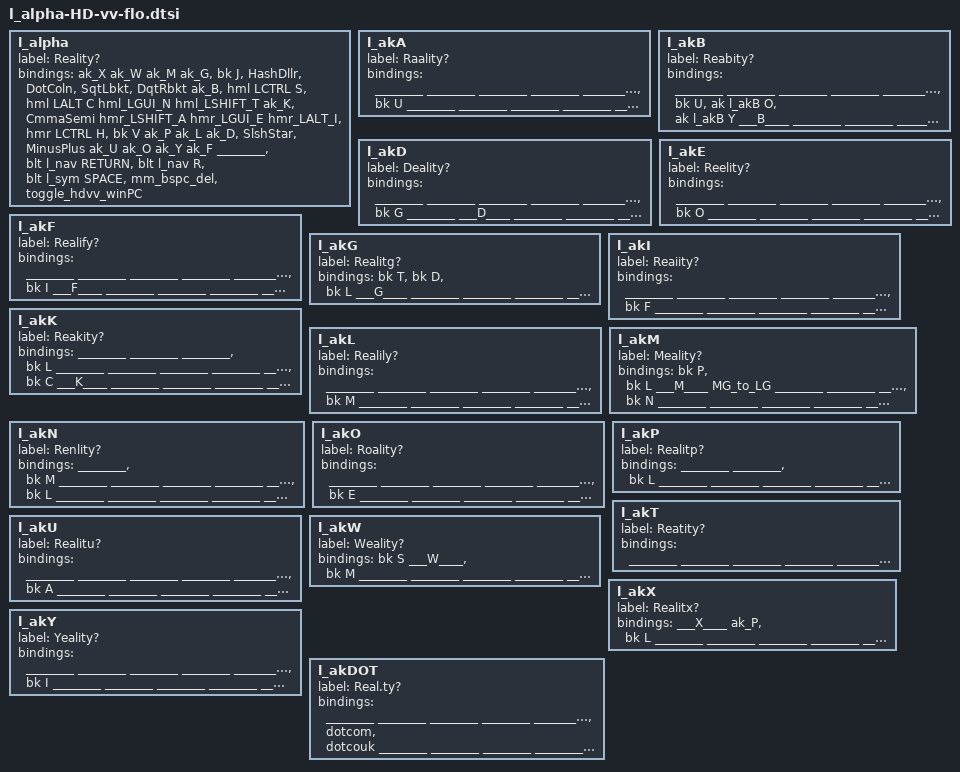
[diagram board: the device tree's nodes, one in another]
#define ________  &trans
#define ___A____ ________
#define ___B____ ________
#define ___C____ ________
#define ___D____ ________
#define ___E____ ________
#define ___F____ ________
#define ___G____ ________
#define ___H____ ________
#define ___I____ ________
#define ___J____ ________
#define ___K____ ________
#define ___L____ ________
#define ___M____ ________
#define ___N____ ________
#define ___O____ ________
#define ___P____ ________
#define ___Q____ ________
#define ___R____ ________
#define ___S____ ________
#define ___T____ ________
#define ___U____ ________
#define ___V____ ________
#define ___W____ ________
#define ___X____ ________
#define ___Y____ ________
#define ___Z____ ________
#define _DOT____ ________


#define GK_to_LK &replace_char_with_bigram L K
#define MG_to_LG &replace_char_with_bigram L G
#define TK_to_CK &replace_char_with_bigram C K


#define XXX 0
// Second param is ignored, so using XXX
#define hml_LGUI_N   &hml_N LGUI   XXX
#define hml_LSHIFT_T &hml_T LSHIFT XXX
#define hmr_LSHIFT_A &hmr_A LSHIFT XXX
#define hmr_LGUI_E   &hmr_E LGUI   XXX
#define hmr_LALT_I   &hmr_I LALT   XXX



                l_alpha {
                        label = "Reality?"; // The base layer ... ?
                        bindings = <

ak_X          ak_W         ak_M         ak_G            &bk J                          &HashDllr   &DotColn      &SqtLbkt    &DqtRbkt    ak_B

&hml LCTRL S  &hml LALT C  hml_LGUI_N   hml_LSHIFT_T    ak_K                           &CmmaSemi   hmr_LSHIFT_A  hmr_LGUI_E  hmr_LALT_I  &hmr LCTRL H

&bk V         ak_P         ak_L         ak_D            &SlshStar                      &MinusPlus  ak_U          ak_O        ak_Y        ak_F

                        ________       &blt l_nav RETURN    &blt l_nav R        &blt l_sym SPACE &mm_bspc_del &toggle_hdvv_winPC
                        >;
                };

                l_akA {
                        label = "Raality?";
                        bindings = <
________   ________   ________   ________   ________          ________   ________   ________   ________   ________
________   ________   ________   ________   ________          ________   ___A____   ________   ________   &bk U
________   ________   ________   ________   ________          ________   ________   ________   ________   ________
                        ________   ________   ________      ________   ________   ________
                        >;
                };

                l_akB {
                        label = "Reabity?";
                        bindings = <
________   ________   ________   ________   ________          ________   &bk U      &ak l_akB O   &ak l_akB Y   ___B____
________   ________   ________   ________   ________          ________   ________   ________      ________      ________
________   ________   ________   ________   ________          ________   ________   ________      ________      ________
                        ________   ________   ________      ________   ________   ________
                        >;
                };

                l_akD {
                        label = "Deality?";
                        bindings = <
________   ________   ________   ________   ________          ________   ________   ________   ________   ________
________   ________   ________   ________   ________          ________   ________   ________   ________   ________
________   &bk G      ________   ___D____   ________          ________   ________   ________   ________   ________
                        ________   ________   ________      ________   ________   ________
                        >;
                };

                l_akE {
                        label = "Reelity?"; // The base layer ... ?
                        bindings = <
________   ________   ________   ________   ________          ________   ________   ________   ________   ________
________   ________   ________   ________   ________          ________   ________   ___E____   ________   &bk O
________   ________   ________   ________   ________          ________   ________   ________   ________   ________
                        ________   ________   ________      ________   ________   ________
                        >;
                };

                l_akF {
                        label = "Realify?";
                        bindings = <
________   ________   ________   ________   ________          ________   ________   ________   ________   ________
________   ________   ________   ________   ________          ________   ________   ________   ________   ________
________   ________   ________   ________   ________          ________   ________   ________   &bk I      ___F____
                        ________   ________   ________      ________   ________   ________
                        >;
                };

                l_akG {
                        label = "Realitg?";
                        bindings = <
&bk T      &bk D      &bk L      ___G____   ________          ________   ________   ________   ________   ________
________   ________   ________   ________   GK_to_LK          ________   ________   ________   ________   ________
________   ________   ________   ________   ________          ________   ________   ________   ________   ________
                        ________   ________   ________      ________   ________   ________
                        >;
                };

                l_akI {
                        label = "Reaiity?";
                        bindings = <
________   ________   ________   ________   ________          ________   ________   ________   ________   ________
________   ________   ________   ________   ________          ________   ________   ________   ___I____   &bk F
________   ________   ________   ________   ________          ________   ________   ________   ________   ________
                        ________   ________   ________      ________   ________   ________
                        >;
                };

                l_akK {
                        label = "Reakity?";
                        bindings = <
________   ________   ________   &bk L      ________          ________   ________   ________   ________   ________
________   ________   ________   &bk C      ___K____          ________   ________   ________   ________   ________
________   ________   ________   ________   ________          ________   ________   ________   ________   ________
                        ________   ________   ________      ________   ________   ________
                        >;
                };


                l_akL {
                        label = "Realily?";
                        bindings = <
________   ________   ________   ________   ________          ________   ________   ________   ________   ________
________   &bk M      ________   ________   ________          ________   ________   ________   ________   ________
________   ________   ___L____   ________   ________          ________   ________   ________   ________   ________
                        ________   ________   ________      ________   ________   ________
                        >;
                };


                l_akM {
                        label = "Meality?";
                        bindings = <
&bk P      &bk L      ___M____   MG_to_LG   ________          ________   ________   ________   ________   ________
________   &bk N      ________   ________   ________          ________   ________   ________   ________   ________
________   ________   ________   ________   ________          ________   ________   ________   ________   ________
                        ________   ________   ________      ________   ________   ________
                        >;
                };

                l_akN {
                        label = "Renlity?";
                        bindings = <
________   &bk M      ________   ________   ________          ________   ________   ________   ________   ________
________   ________   ___N____   ________   ________          ________   ________   ________   ________   ________
________   &bk L      ________   ________   ________          ________   ________   ________   ________   ________
                        ________   ________   ________      ________   ________   ________
                        >;
                };

                l_akO {
                        label = "Roality?";
                        bindings = <
________   ________   ________   ________   ________          ________   ________   ________   ________   ________
________   ________   ________   ________   ________          ________   ________   ________   ________   &bk E
________   ________   ________   ________   ________          ________   ________   ___O____   ________   ________
                        ________   ________   ________      ________   ________   ________
                        >;
                };

                l_akP {
                        label = "Realitp?";
                        bindings = <
________   ________   &bk L      ________   ________          ________   ________   ________   ________   ________
________   ________   ________   ________   ________          ________   ________   ________   ________   ________
________   ___P____   ________   ________   ________          ________   ________   ________   ________   ________
                        ________   ________   ________      ________   ________   ________
                        >;
                };

                l_akT {
                        label = "Reatity?";
                        bindings = <
________   ________   ________   ________   ________          ________   ________   ________   ________   ________
________   ________   ________   ___T____   TK_to_CK          ________   ________   ________   ________   ________
________   ________   ________   ________   ________          ________   ________   ________   ________   ________
                        ________   ________   ________      ________   ________   ________
                        >;
                };

                l_akU {
                        label = "Realitu?";
                        bindings = <
________   ________   ________   ________   ________          ________   ________   ________   ________   ________
________   ________   ________   ________   ________          ________   ________   ________   ________   &bk A
________   ________   ________   ________   ________          ________   ___U____   ________   ________   ________
                        ________   ________   ________      ________   ________   ________
                        >;
                };

                l_akW {
                        label = "Weality?";
                        bindings = <
&bk S      ___W____   &bk M      ________   ________          ________   ________   ________   ________   ________
________   ________   ________   ________   ________          ________   ________   ________   ________   ________
________   ________   ________   ________   ________          ________   ________   ________   ________   ________
                        ________   ________   ________      ________   ________   ________
                        >;
                };

                l_akX {
                        label = "Realitx?";
                        bindings = <
___X____   ak_P       &bk L      ________   ________          ________   ________   ________   ________   ________
________   ________   ________   ________   ________          ________   ________   ________   ________   ________
________   ________   ________   ________   ________          ________   ________   ________   ________   ________
                        ________   ________   ________      ________   ________   ________
                        >;
                };

                l_akY {
                        label = "Yeality?";
                        bindings = <
________   ________   ________   ________   ________          ________   ________   ________   ________   ________
________   ________   ________   ________   ________          ________   ________   ________   ________   ________
________   ________   ________   ________   ________          ________   ________   ________   ___Y____   &bk I
                        ________   ________   ________      ________   ________   ________
                        >;
                };

                l_akDOT {
                        label = "Real.ty?";
                        bindings = <
________   ________   ________   ________   ________          ________   _DOT____   &dotcom    &dotcouk   ________
________   ________   ________   ________   ________          ________   ________   ________   ________   ________
________   ________   ________   ________   ________          ________   ________   ________   ________   ________
                        ________   ________   ________      ________   ________   ________
                        >;
                };
